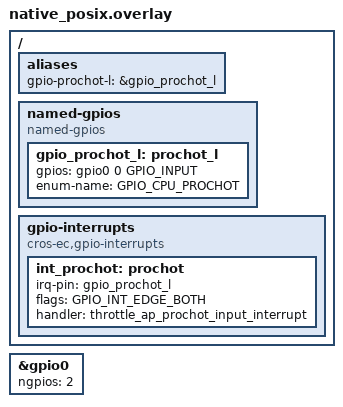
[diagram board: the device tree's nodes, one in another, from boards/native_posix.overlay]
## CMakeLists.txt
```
# Copyright 2021 The ChromiumOS Authors
# Use of this source code is governed by a BSD-style license that can be
# found in the LICENSE file.

cmake_minimum_required(VERSION 3.13.1)
find_package(Zephyr REQUIRED HINTS "${ZEPHYR_BASE}")
project(throttle_ap)

add_subdirectory(${PLATFORM_EC}/zephyr/test/test_utils test_utils)

zephyr_include_directories("${CMAKE_CURRENT_SOURCE_DIR}/include")

target_sources_ifdef(CONFIG_TEST_INTERRUPT app PRIVATE src/interrupt.c)
target_sources_ifdef(CONFIG_TEST_THROTTLE_AP app PRIVATE src/throttle_ap.c)
target_sources(app PRIVATE src/common.c)
```

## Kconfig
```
# Copyright 2022 The ChromiumOS Authors
# Use of this source code is governed by a BSD-style license that can be
# found in the LICENSE file.

source "Kconfig.zephyr"

config AP_POWER_CONTROL
	bool "Allows the test to mock various chipset functions"
	default y

config TEST_INTERRUPT
	bool "Enable testing of prochot interrupts"
	default n

config TEST_THROTTLE_AP
	bool "Enable testing of AP throttling functions"
	default n
```

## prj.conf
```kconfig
# Copyright 2022 The ChromiumOS Authors
# Use of this source code is governed by a BSD-style license that can be
# found in the LICENSE file.

CONFIG_ZTEST=y
CONFIG_ZTEST_ASSERT_VERBOSE=1
CONFIG_ZTEST_MOCKING=y
CONFIG_ZTEST_PARAMETER_COUNT=24
CONFIG_TEST=y
CONFIG_ASSERT=y

# Print logs from Zephyr LOG_MODULE to stdout
CONFIG_UART_NATIVE_PTY_0_ON_STDINOUT=y

# Simulate 10 ticks per ms
CONFIG_SYS_CLOCK_TICKS_PER_SEC=10000
CONFIG_TASKS_SET_TEST_RUNNER_TID_RULE=y

# Enable exception stack traces for better errors
CONFIG_EXCEPTION_STACK_TRACE=y

# Enable debugging features
CONFIG_DEBUG=y
CONFIG_X86_DEBUG_INFO=y
CONFIG_DEBUG_OPTIMIZATIONS=y
CONFIG_PLATFORM_EC_CONSOLE_DEBUG=y
CONFIG_SHELL_BACKEND_DUMMY=y
CONFIG_SHELL_BACKEND_SERIAL=n
# We aren't using the serial console, but there is still a lot of code that
# assumes that a serial port exists.
CONFIG_SERIAL=y

CONFIG_PLATFORM_EC=y
CONFIG_CROS_EC=y
CONFIG_SHIMMED_TASKS=y
CONFIG_EMUL=y
CONFIG_GPIO=y
CONFIG_HEAP_MEM_POOL_SIZE=1024

CONFIG_PLATFORM_EC_THROTTLE_AP=y
CONFIG_PLATFORM_EC_THROTTLE_AP_SINGLE_PIN=y
CONFIG_PLATFORM_EC_CONSOLE_CMD_APTHROTTLE=n
```

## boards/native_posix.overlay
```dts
/* Copyright 2022 The ChromiumOS Authors
 * Use of this source code is governed by a BSD-style license that can be
 * found in the LICENSE file.
 */

#include <board-overlays/native_posix.dts>
#include <dt-bindings/gpio_defines.h>

/ {
	aliases {
		gpio-prochot-l = &gpio_prochot_l;
	};
	/*
	 * Keep these GPIOs in pin order.
	 * If you need to add one, make sure you increase
	 * ngpios in the gpio0 node further down.
	 */
	named-gpios {
		compatible = "named-gpios";

		gpio_prochot_l: prochot_l {
			gpios = <&gpio0 0 GPIO_INPUT>;
			enum-name = "GPIO_CPU_PROCHOT";
		};
	};
	gpio-interrupts {
		compatible = "cros-ec,gpio-interrupts";

		int_prochot: prochot {
			irq-pin = <&gpio_prochot_l>;
			flags = <GPIO_INT_EDGE_BOTH>;
			handler = "throttle_ap_prochot_input_interrupt";
		};
	};
};

&gpio0 {
	ngpios = <2>;
};
```

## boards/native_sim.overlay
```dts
/* Copyright 2022 The ChromiumOS Authors
 * Use of this source code is governed by a BSD-style license that can be
 * found in the LICENSE file.
 */

#include <board-overlays/native_sim.dts>
#include <dt-bindings/gpio_defines.h>

/ {
	aliases {
		gpio-prochot-l = &gpio_prochot_l;
	};
	/*
	 * Keep these GPIOs in pin order.
	 * If you need to add one, make sure you increase
	 * ngpios in the gpio0 node further down.
	 */
	named-gpios {
		compatible = "named-gpios";

		gpio_prochot_l: prochot_l {
			gpios = <&gpio0 0 GPIO_INPUT>;
			enum-name = "GPIO_CPU_PROCHOT";
		};
	};
	gpio-interrupts {
		compatible = "cros-ec,gpio-interrupts";

		int_prochot: prochot {
			irq-pin = <&gpio_prochot_l>;
			flags = <GPIO_INT_EDGE_BOTH>;
			handler = "throttle_ap_prochot_input_interrupt";
		};
	};
};

&gpio0 {
	ngpios = <2>;
};
```

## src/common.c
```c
/* Copyright 2022 The ChromiumOS Authors
 * Use of this source code is governed by a BSD-style license that can be
 * found in the LICENSE file.
 */
#include <zephyr/ztest.h>

#include <chipset.h>
#include <console.h>
#include <throttle_ap.h>

ZTEST_SUITE(throttle_ap, NULL, NULL, NULL, NULL, NULL);

/*
 * The prochot interrupt handler will return early if the chipset is
 * off or suspended.
 */
int chipset_in_state(int state_mask)
{
	return state_mask & CHIPSET_STATE_ON;
}

void chipset_force_shutdown(enum chipset_shutdown_reason reason)
{
}

int extpower_is_present(void)
{
	return 1;
}
```

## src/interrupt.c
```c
/* Copyright 2022 The ChromiumOS Authors
 * Use of this source code is governed by a BSD-style license that can be
 * found in the LICENSE file.
 */
#include <stdint.h>

#include <zephyr/drivers/gpio.h>
#include <zephyr/drivers/gpio/gpio_emul.h>
#include <zephyr/kernel.h>
#include <zephyr/ztest.h>

#include <gpio.h>
#include <throttle_ap.h>
#include <timer.h>

#define PROCHOT_ASSERTED \
	!IS_ENABLED(PLATFORM_EC_POWERSEQ_CPU_PROCHOT_ACTIVE_LOW)

/* Waits for the debouncing logic to finish. */
static void debounce_wait(void)
{
	k_usleep(PROCHOT_IN_DEBOUNCE_US);
	k_msleep(1);
}

static bool was_asserted;
static void callback(bool asserted, void *data)
{
	was_asserted = asserted;
}

const struct prochot_cfg cfg = {
	.gpio_prochot_in = GPIO_CPU_PROCHOT,
	.callback = &callback,

};

ZTEST_USER(throttle_ap, test_interrupts)
{
	const struct device *dev =
		DEVICE_DT_GET(DT_GPIO_CTLR(DT_ALIAS(gpio_prochot_l), gpios));
	const gpio_port_pins_t pin =
		DT_GPIO_PIN(DT_ALIAS(gpio_prochot_l), gpios);

	/* Start the test with the interrupt deasserted. */
	zassert_ok(gpio_emul_input_set(dev, pin, !PROCHOT_ASSERTED));

	throttle_ap_config_prochot(&cfg);
	gpio_enable_interrupt(cfg.gpio_prochot_in);

	zassert_ok(gpio_emul_input_set(dev, pin, PROCHOT_ASSERTED));
	debounce_wait();
	zassert_true(was_asserted);

	zassert_ok(gpio_emul_input_set(dev, pin, !PROCHOT_ASSERTED));
	debounce_wait();
	zassert_false(was_asserted);
}
```

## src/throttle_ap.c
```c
/* Copyright 2022 The ChromiumOS Authors
 * Use of this source code is governed by a BSD-style license that can be
 * found in the LICENSE file.
 */
#include "common.h"

#include <zephyr/ztest.h>

#include <chipset.h>
#include <console.h>
#include <gpio.h>
#include <throttle_ap.h>

static bool is_throttled;
void chipset_throttle_cpu(int throttle)
{
	is_throttled = throttle;
}

ZTEST_USER(throttle_ap, test_throttle_ap)
{
	throttle_ap(THROTTLE_ON, THROTTLE_HARD, THROTTLE_SRC_AC);
	zassert_true(is_throttled);

	throttle_ap(THROTTLE_OFF, THROTTLE_HARD, THROTTLE_SRC_AC);
	zassert_false(is_throttled);
}

ZTEST_USER(throttle_ap, test_command_apthrottle)
{
	/* Must define CONFIG_CMD_APTHROTTLE for this sub-command */
	int rv = shell_execute_cmd(get_ec_shell(), "apthrottle");

	zassert_equal(rv, 0, "Expected %d, but got %d", 0, rv);
}
```
